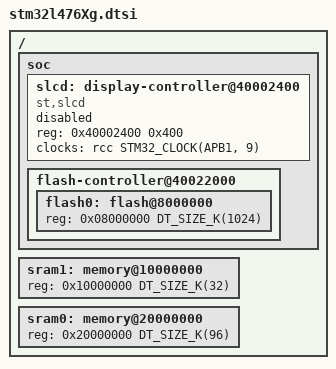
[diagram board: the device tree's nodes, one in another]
/*
 * Copyright (c) 2018 Linaro Limited
 *
 * SPDX-License-Identifier: Apache-2.0
 */
#include <st/l4/stm32l476.dtsi>

/ {
	soc {
		slcd: display-controller@40002400 {
			compatible = "st,slcd";
			reg = <0x40002400 0x400>;
			clocks = <&rcc STM32_CLOCK(APB1, 9)>;
			status = "disabled";
		};

		flash-controller@40022000 {
			flash0: flash@8000000 {
				reg = <0x08000000 DT_SIZE_K(1024)>;
				ranges = <0 0x8000000 DT_SIZE_K(1024)>;
			};
		};
	};

	sram1: memory@10000000 {
		reg = <0x10000000 DT_SIZE_K(32)>;
	};

	sram0: memory@20000000 {
		reg = <0x20000000 DT_SIZE_K(96)>;
	};
};
